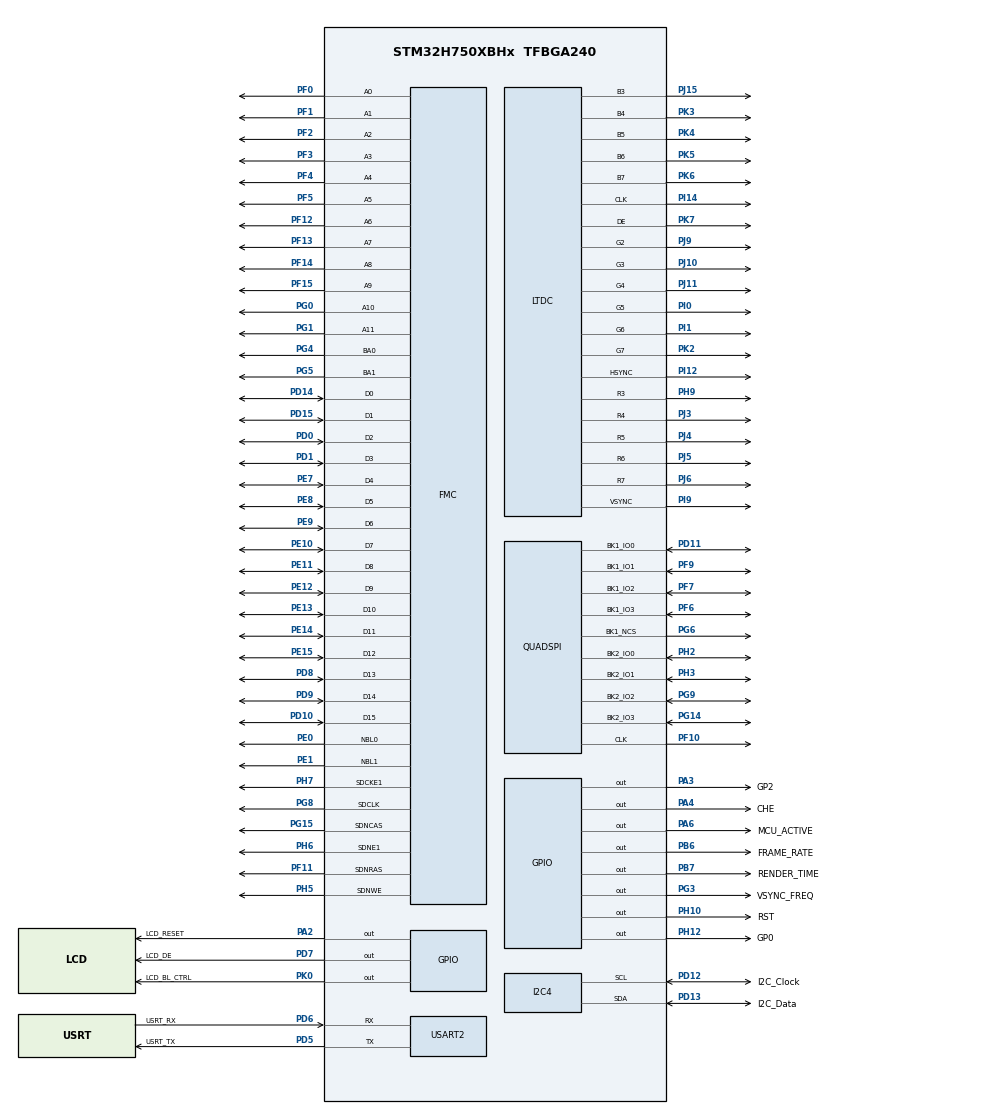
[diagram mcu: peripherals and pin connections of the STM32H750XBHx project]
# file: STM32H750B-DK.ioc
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CORTEX_M7.AccessPermission-Cortex_Memory_Protection_Unit_Region0_Settings=MPU_REGION_FULL_ACCESS
CORTEX_M7.AccessPermission-Cortex_Memory_Protection_Unit_Region1_Settings=MPU_REGION_NO_ACCESS
CORTEX_M7.AccessPermission-Cortex_Memory_Protection_Unit_Region2_Settings=MPU_REGION_FULL_ACCESS
CORTEX_M7.AccessPermission-Cortex_Memory_Protection_Unit_Region4_Settings=MPU_REGION_FULL_ACCESS
CORTEX_M7.BaseAddress-Cortex_Memory_Protection_Unit_Region0_Settings=0x24000000
CORTEX_M7.BaseAddress-Cortex_Memory_Protection_Unit_Region1_Settings=0x90000000
CORTEX_M7.BaseAddress-Cortex_Memory_Protection_Unit_Region2_Settings=0x90000000
CORTEX_M7.BaseAddress-Cortex_Memory_Protection_Unit_Region3_Settings=0xD0000000
CORTEX_M7.BaseAddress-Cortex_Memory_Protection_Unit_Region4_Settings=0xD0000000
CORTEX_M7.CPU_DCache=Enabled
CORTEX_M7.CPU_ICache=Enabled
CORTEX_M7.DisableExec-Cortex_Memory_Protection_Unit_Region0_Settings=MPU_INSTRUCTION_ACCESS_DISABLE
CORTEX_M7.DisableExec-Cortex_Memory_Protection_Unit_Region1_Settings=MPU_INSTRUCTION_ACCESS_DISABLE
CORTEX_M7.DisableExec-Cortex_Memory_Protection_Unit_Region2_Settings=MPU_INSTRUCTION_ACCESS_ENABLE
CORTEX_M7.DisableExec-Cortex_Memory_Protection_Unit_Region3_Settings=MPU_INSTRUCTION_ACCESS_DISABLE
CORTEX_M7.DisableExec-Cortex_Memory_Protection_Unit_Region4_Settings=MPU_INSTRUCTION_ACCESS_DISABLE
CORTEX_M7.Enable-Cortex_Memory_Protection_Unit_Region0_Settings=MPU_REGION_ENABLE
CORTEX_M7.Enable-Cortex_Memory_Protection_Unit_Region1_Settings=MPU_REGION_ENABLE
CORTEX_M7.Enable-Cortex_Memory_Protection_Unit_Region2_Settings=MPU_REGION_ENABLE
CORTEX_M7.Enable-Cortex_Memory_Protection_Unit_Region3_Settings=MPU_REGION_ENABLE
CORTEX_M7.Enable-Cortex_Memory_Protection_Unit_Region4_Settings=MPU_REGION_ENABLE
CORTEX_M7.IsBufferable-Cortex_Memory_Protection_Unit_Region0_Settings=MPU_ACCESS_BUFFERABLE
CORTEX_M7.IsBufferable-Cortex_Memory_Protection_Unit_Region1_Settings=MPU_ACCESS_NOT_BUFFERABLE
CORTEX_M7.IsBufferable-Cortex_Memory_Protection_Unit_Region2_Settings=MPU_ACCESS_BUFFERABLE
CORTEX_M7.IsCacheable-Cortex_Memory_Protection_Unit_Region0_Settings=MPU_ACCESS_CACHEABLE
CORTEX_M7.IsCacheable-Cortex_Memory_Protection_Unit_Region1_Settings=MPU_ACCESS_NOT_CACHEABLE
CORTEX_M7.IsCacheable-Cortex_Memory_Protection_Unit_Region2_Settings=MPU_ACCESS_CACHEABLE
CORTEX_M7.IsCacheable-Cortex_Memory_Protection_Unit_Region4_Settings=MPU_ACCESS_CACHEABLE
CORTEX_M7.IsShareable-Cortex_Memory_Protection_Unit_Region2_Settings=MPU_ACCESS_NOT_SHAREABLE
CORTEX_M7.IsShareable-Cortex_Memory_Protection_Unit_Region4_Settings=MPU_ACCESS_NOT_SHAREABLE
CORTEX_M7.MPU_Control=MPU_PRIVILEGED_DEFAULT
CORTEX_M7.Size-Cortex_Memory_Protection_Unit_Region0_Settings=MPU_REGION_SIZE_512KB
CORTEX_M7.Size-Cortex_Memory_Protection_Unit_Region1_Settings=MPU_REGION_SIZE_256MB
CORTEX_M7.Size-Cortex_Memory_Protection_Unit_Region2_Settings=MPU_REGION_SIZE_128MB
CORTEX_M7.Size-Cortex_Memory_Protection_Unit_Region3_Settings=MPU_REGION_SIZE_256MB
CORTEX_M7.Size-Cortex_Memory_Protection_Unit_Region4_Settings=MPU_REGION_SIZE_32MB
DMA2D.ColorMode=DMA2D_OUTPUT_RGB565
FMC.CASLatency2=FMC_SDRAM_CAS_LATENCY_3
FMC.ColumnBitsNumber2=FMC_SDRAM_COLUMN_BITS_NUM_8
FMC.ExitSelfRefreshDelay2=7
FMC.LoadToActiveDelay2=2
FMC.RCDDelay2=2
FMC.RPDelay2=2
FMC.ReadBurst2=FMC_SDRAM_RBURST_ENABLE
FMC.RowCycleDelay2=7
FMC.SDClockPeriod2=FMC_SDRAM_CLOCK_PERIOD_2
FMC.SelfRefreshTime2=4
FMC.WriteRecoveryTime2=5
FREERTOS.BinarySemaphores01=semaphoreHaltUntilString,Dynamic,NULL;semaphoreTransitionFromHomeByButtonSettings,Dynamic,NULL;semaphoreUART,Dynamic,NULL;semaphoreTransitionFromHomeByButtonDisconnect,Dynamic,NULL
FREERTOS.Events01=eventESPBasicSetUpFinished,Dynamic,NULL;eventESPResponseValid,Dynamic,NULL;eventESPResponse,Dynamic,NULL;eventConfigurationsLoaded,Dynamic,NULL;eventESPWifiConnected,Dynamic,NULL;eventESPServerConnected,Dynamic,NULL;eventDisconnect,Dynamic,NULL
FREERTOS.HEAP_NUMBER=4
FREERTOS.Mutexes01=MutexI2C4,Dynamic,NULL
FREERTOS.Queues01=queueTempAndHumid,16,float,0,Dynamic,NULL,NULL;queueRxDataChar,512,uint8_t,0,Dynamic,NULL,NULL;queueTouchgfxTempAndHumid,16,float,0,Dynamic,NULL,NULL
FREERTOS.Tasks01=defaultTask,24,256,StartDefaultTask,Default,NULL,Dynamic,NULL,NULL;GUITask,24,8096,TouchGFX_Task,As external,NULL,Dynamic,NULL,NULL;videoTask,8,2048,videoTaskFunc,As external,NULL,Dynamic,NULL,NULL;SendDataWithESP,32,256,prvTaskSendDataWithESP,Default,NULL,Dynamic,NULL,NULL;SetUpESP,24,256,prvTaskSetUpESP,Default,NULL,Dynamic,NULL,NULL;ReadSensorData,32,256,prvTaskReadTempAndHumidity,Default,NULL,Dynamic,NULL,NULL;ReadESP,40,256,prvTaskReadESP,Default,NULL,Dynamic,NULL,NULL;ConnectToWifi,24,256,prvTaskConnectToWifi,Default,NULL,Dynamic,NULL,NULL;ConnectToServer,24,256,prvTaskConnectToServer,Default,NULL,Dynamic,NULL,NULL;Disconnect,40,256,prvTaskDisconnect,Default,NULL,Dynamic,NULL,NULL
FREERTOS.configMINIMAL_STACK_SIZE=256
FREERTOS.configTOTAL_HEAP_SIZE=100000
FREERTOS.configUSE_APPLICATION_TASK_TAG=1
FREERTOS.configUSE_IDLE_HOOK=1
FREERTOS.configUSE_MALLOC_FAILED_HOOK=0
FREERTOS.configUSE_NEWLIB_REENTRANT=0
I2C4.Timing=0x10C0ECFF
JPEG.JPEG_RGB_FORMAT=JPEG_RGB565
LIBJPEG.RGB_ORDERING=BGR
LTDC.ActiveH=272
LTDC.ActiveW=480
LTDC.Alpha_L0=255
LTDC.BlendingFactor1_L0=LTDC_BLENDING_FACTOR1_CA
LTDC.BlendingFactor2_L0=LTDC_BLENDING_FACTOR2_CA
LTDC.HBP=3
LTDC.HSync=40
LTDC.ImageHeight_L0=272
LTDC.ImageWidth_L0=480
LTDC.Layers=0
LTDC.PixelFormat_L0=LTDC_PIXEL_FORMAT_RGB565
LTDC.VBP=3
LTDC.VSync=9
LTDC.WindowX1_L0=480
LTDC.WindowY1_L0=272
Mcu.Family=STM32H7
Mcu.Name=STM32H750XBHx
Mcu.Package=TFBGA240
Mdma.MDMA_Channel6.JPEG_OUTFIFO_TH.0.BlockCount=0
Mdma.MDMA_Channel6.JPEG_OUTFIFO_TH.0.BlockDataLength=0
Mdma.MDMA_Channel6.JPEG_OUTFIFO_TH.0.BufferTransferLength=32
Mdma.MDMA_Channel6.JPEG_OUTFIFO_TH.0.CircularMode=MDMA_LINEAR_LIST
Mdma.MDMA_Channel6.JPEG_OUTFIFO_TH.0.DataAlignment=MDMA_DATAALIGN_PACKENABLE
Mdma.MDMA_Channel6.JPEG_OUTFIFO_TH.0.DestBlockAddressOffset=0
Mdma.MDMA_Channel6.JPEG_OUTFIFO_TH.0.DestBurst=MDMA_DEST_BURST_32BEATS
Mdma.MDMA_Channel6.JPEG_OUTFIFO_TH.0.DestDataSize=MDMA_DEST_DATASIZE_BYTE
Mdma.MDMA_Channel6.JPEG_OUTFIFO_TH.0.DestinationInc=MDMA_DEST_INC_BYTE
Mdma.MDMA_Channel6.JPEG_OUTFIFO_TH.0.DstAddress=0
Mdma.MDMA_Channel6.JPEG_OUTFIFO_TH.0.Endianness=MDMA_LITTLE_ENDIANNESS_PRESERVE
Mdma.MDMA_Channel6.JPEG_OUTFIFO_TH.0.Instance=MDMA_Channel6
Mdma.MDMA_Channel6.JPEG_OUTFIFO_TH.0.MaskAddress=0
Mdma.MDMA_Channel6.JPEG_OUTFIFO_TH.0.MaskData=0
Mdma.MDMA_Channel6.JPEG_OUTFIFO_TH.0.Priority=MDMA_PRIORITY_VERY_HIGH
Mdma.MDMA_Channel6.JPEG_OUTFIFO_TH.0.Rank=First
Mdma.MDMA_Channel6.JPEG_OUTFIFO_TH.0.SourceBlockAddressOffset=0
Mdma.MDMA_Channel6.JPEG_OUTFIFO_TH.0.SourceBurst=MDMA_SOURCE_BURST_32BEATS
Mdma.MDMA_Channel6.JPEG_OUTFIFO_TH.0.SourceDataSize=MDMA_SRC_DATASIZE_WORD
Mdma.MDMA_Channel6.JPEG_OUTFIFO_TH.0.SourceInc=MDMA_SRC_INC_DISABLE
Mdma.MDMA_Channel6.JPEG_OUTFIFO_TH.0.SrcAddress=0
Mdma.MDMA_Channel6.JPEG_OUTFIFO_TH.0.TransferTriggerMode=MDMA_BUFFER_TRANSFER
Mdma.MDMA_Channel6.Request0=JPEG_OUTFIFO_TH
Mdma.MDMA_Channel6.RequestsNb=1
Mdma.MDMA_Channel7.JPEG_INFIFO_TH.0.BlockCount=0
Mdma.MDMA_Channel7.JPEG_INFIFO_TH.0.BlockDataLength=0
Mdma.MDMA_Channel7.JPEG_INFIFO_TH.0.BufferTransferLength=32
Mdma.MDMA_Channel7.JPEG_INFIFO_TH.0.CircularMode=MDMA_LINEAR_LIST
Mdma.MDMA_Channel7.JPEG_INFIFO_TH.0.DataAlignment=MDMA_DATAALIGN_PACKENABLE
Mdma.MDMA_Channel7.JPEG_INFIFO_TH.0.DestBlockAddressOffset=0
Mdma.MDMA_Channel7.JPEG_INFIFO_TH.0.DestBurst=MDMA_DEST_BURST_16BEATS
Mdma.MDMA_Channel7.JPEG_INFIFO_TH.0.DestDataSize=MDMA_DEST_DATASIZE_WORD
Mdma.MDMA_Channel7.JPEG_INFIFO_TH.0.DestinationInc=MDMA_DEST_INC_DISABLE
Mdma.MDMA_Channel7.JPEG_INFIFO_TH.0.DstAddress=0
Mdma.MDMA_Channel7.JPEG_INFIFO_TH.0.Endianness=MDMA_LITTLE_ENDIANNESS_PRESERVE
Mdma.MDMA_Channel7.JPEG_INFIFO_TH.0.Instance=MDMA_Channel7
Mdma.MDMA_Channel7.JPEG_INFIFO_TH.0.MaskAddress=0
Mdma.MDMA_Channel7.JPEG_INFIFO_TH.0.MaskData=0
Mdma.MDMA_Channel7.JPEG_INFIFO_TH.0.Priority=MDMA_PRIORITY_HIGH
Mdma.MDMA_Channel7.JPEG_INFIFO_TH.0.Rank=First
Mdma.MDMA_Channel7.JPEG_INFIFO_TH.0.SourceBlockAddressOffset=0
Mdma.MDMA_Channel7.JPEG_INFIFO_TH.0.SourceBurst=MDMA_SOURCE_BURST_32BEATS
Mdma.MDMA_Channel7.JPEG_INFIFO_TH.0.SourceDataSize=MDMA_SRC_DATASIZE_BYTE
Mdma.MDMA_Channel7.JPEG_INFIFO_TH.0.SourceInc=MDMA_SRC_INC_BYTE
Mdma.MDMA_Channel7.JPEG_INFIFO_TH.0.SrcAddress=0
Mdma.MDMA_Channel7.JPEG_INFIFO_TH.0.TransferTriggerMode=MDMA_BUFFER_TRANSFER
Mdma.MDMA_Channel7.Request0=JPEG_INFIFO_TH
Mdma.MDMA_Channel7.RequestsNb=1
Mdma.RequestSet0=MDMA_Channel7
Mdma.RequestSet1=MDMA_Channel6
Mdma.RequestSetsNb=2
NVIC.DMA2D_IRQn=true\:5\:0\:true\:false\:true\:false\:true\:true\:true
NVIC.JPEG_IRQn=true\:5\:0\:false\:false\:true\:true\:true\:true\:true
NVIC.LTDC_IRQn=true\:5\:0\:true\:false\:true\:false\:true\:true\:true
NVIC.MDMA_IRQn=true\:5\:0\:false\:false\:true\:true\:false\:true\:true
NVIC.PriorityGroup=NVIC_PRIORITYGROUP_4
NVIC.TIM6_DAC_IRQn=true\:0\:0\:false\:false\:true\:false\:false\:true\:true
NVIC.TimeBase=TIM6_DAC_IRQn
NVIC.TimeBaseIP=TIM6
NVIC.USART2_IRQn=true\:5\:0\:false\:false\:true\:true\:true\:true\:true
PA2.GPIO_Label=LCD_RESET
PA2.Signal=GPIO_Output
PA3.GPIO_Label=GP2
PA3.GPIO_PuPd=GPIO_PULLUP
PA3.PinState=GPIO_PIN_SET
PA3.Signal=GPIO_Output
PA4.GPIO_Label=CHE
PA4.GPIO_PuPd=GPIO_PULLUP
PA4.PinState=GPIO_PIN_SET
PA4.Signal=GPIO_Output
PA6.GPIO_Label=MCU_ACTIVE
PA6.GPIO_Speed=GPIO_SPEED_FREQ_VERY_HIGH
PA6.Signal=GPIO_Output
PB6.GPIO_Label=FRAME_RATE
PB6.GPIO_Speed=GPIO_SPEED_FREQ_VERY_HIGH
PB6.Signal=GPIO_Output
PB7.GPIO_Label=RENDER_TIME
PB7.GPIO_Speed=GPIO_SPEED_FREQ_VERY_HIGH
PB7.Signal=GPIO_Output
PD0.Signal=FMC_D2_DA2
PD1.Signal=FMC_D3_DA3
PD10.Signal=FMC_D15_DA15
PD11.GPIO_Speed=GPIO_SPEED_FREQ_VERY_HIGH
PD11.Mode=Dual_Bank
PD11.Signal=QUADSPI_BK1_IO0
PD12.GPIO_Label=I2C_Clock
PD12.Mode=I2C
PD12.Signal=I2C4_SCL
PD13.GPIO_Label=I2C_Data
PD13.Mode=I2C
PD13.Signal=I2C4_SDA
PD14.Signal=FMC_D0_DA0
PD15.Signal=FMC_D1_DA1
PD5.GPIO_Label=USRT_TX
PD5.GPIO_PuPd=GPIO_PULLUP
PD5.Mode=Asynchronous
PD5.Signal=USART2_TX
PD6.GPIO_Label=USRT_RX
PD6.GPIO_PuPd=GPIO_PULLUP
PD6.Mode=Asynchronous
PD6.Signal=USART2_RX
PD7.GPIO_Label=LCD_DE
PD7.Signal=GPIO_Output
PD8.Signal=FMC_D13_DA13
PD9.Signal=FMC_D14_DA14
PE0.Signal=FMC_NBL0
PE1.Signal=FMC_NBL1
PE10.Signal=FMC_D7_DA7
PE11.Signal=FMC_D8_DA8
PE12.Signal=FMC_D9_DA9
PE13.Signal=FMC_D10_DA10
PE14.Signal=FMC_D11_DA11
PE15.Signal=FMC_D12_DA12
PE7.Signal=FMC_D4_DA4
PE8.Signal=FMC_D5_DA5
PE9.Signal=FMC_D6_DA6
PF0.Signal=FMC_A0
PF1.Signal=FMC_A1
PF10.GPIO_Speed=GPIO_SPEED_FREQ_VERY_HIGH
PF10.Mode=Dual_Bank
PF10.Signal=QUADSPI_CLK
PF11.Signal=FMC_SDNRAS
PF12.Signal=FMC_A6
PF13.Signal=FMC_A7
PF14.Signal=FMC_A8
PF15.Signal=FMC_A9
PF2.Signal=FMC_A2
PF3.Signal=FMC_A3
PF4.Signal=FMC_A4
PF5.Signal=FMC_A5
PF6.GPIO_Speed=GPIO_SPEED_FREQ_VERY_HIGH
PF6.Mode=Dual_Bank
PF6.Signal=QUADSPI_BK1_IO3
PF7.GPIO_Speed=GPIO_SPEED_FREQ_VERY_HIGH
PF7.Mode=Dual_Bank
PF7.Signal=QUADSPI_BK1_IO2
PF9.GPIO_Speed=GPIO_SPEED_FREQ_VERY_HIGH
PF9.Mode=Dual_Bank
PF9.Signal=QUADSPI_BK1_IO1
PG0.Signal=FMC_A10
PG1.Signal=FMC_A11
PG14.GPIO_Speed=GPIO_SPEED_FREQ_VERY_HIGH
PG14.Mode=Dual_Bank
PG14.Signal=QUADSPI_BK2_IO3
PG15.Signal=FMC_SDNCAS
PG3.GPIO_Label=VSYNC_FREQ
PG3.GPIO_Speed=GPIO_SPEED_FREQ_VERY_HIGH
PG3.Signal=GPIO_Output
PG4.Signal=FMC_A14_BA0
PG5.Signal=FMC_A15_BA1
PG6.GPIO_Speed=GPIO_SPEED_FREQ_VERY_HIGH
PG6.Mode=Enable Chip Select 1 for both banks
PG6.Signal=QUADSPI_BK1_NCS
PG8.Signal=FMC_SDCLK
PG9.GPIO_Speed=GPIO_SPEED_FREQ_VERY_HIGH
PG9.Mode=Dual_Bank
PG9.Signal=QUADSPI_BK2_IO2
PH0-OSC_IN\ (PH0).Mode=HSE-External-Oscillator
PH0-OSC_IN\ (PH0).Signal=RCC_OSC_IN
PH1-OSC_OUT\ (PH1).Mode=HSE-External-Oscillator
PH1-OSC_OUT\ (PH1).Signal=RCC_OSC_OUT
PH10.GPIO_Label=RST
PH10.GPIO_PuPd=GPIO_PULLUP
PH10.PinState=GPIO_PIN_SET
PH10.Signal=GPIO_Output
PH12.GPIO_Label=GP0
PH12.GPIO_PuPd=GPIO_PULLUP
PH12.PinState=GPIO_PIN_SET
PH12.Signal=GPIO_Output
PH2.GPIO_Speed=GPIO_SPEED_FREQ_VERY_HIGH
PH2.Mode=Dual_Bank
PH2.Signal=QUADSPI_BK2_IO0
PH3.GPIO_Speed=GPIO_SPEED_FREQ_VERY_HIGH
PH3.Mode=Dual_Bank
PH3.Signal=QUADSPI_BK2_IO1
PH5.Signal=FMC_SDNWE
PH6.Mode=SdramChipSelect2_2
PH6.Signal=FMC_SDNE1
PH7.Mode=SdramChipSelect2_2
PH7.Signal=FMC_SDCKE1
PH9.GPIO_Speed=GPIO_SPEED_FREQ_HIGH
PH9.Mode=RGB565
PH9.Signal=LTDC_R3
PI0.GPIO_Speed=GPIO_SPEED_FREQ_HIGH
PI0.Mode=RGB565
PI0.Signal=LTDC_G5
PI1.GPIO_Speed=GPIO_SPEED_FREQ_HIGH
PI1.Mode=RGB565
PI1.Signal=LTDC_G6
PI12.GPIO_Speed=GPIO_SPEED_FREQ_HIGH
PI12.Mode=RGB565
PI12.Signal=LTDC_HSYNC
PI14.GPIO_Speed=GPIO_SPEED_FREQ_HIGH
PI14.Mode=RGB565
PI14.Signal=LTDC_CLK
PI15.GPIO_Speed=GPIO_SPEED_FREQ_HIGH
PI15.Signal=LTDC_R0
PI9.GPIO_Speed=GPIO_SPEED_FREQ_HIGH
PI9.Mode=RGB565
PI9.Signal=LTDC_VSYNC
PJ0.GPIO_Speed=GPIO_SPEED_FREQ_HIGH
PJ0.Signal=LTDC_R1
PJ1.GPIO_Speed=GPIO_SPEED_FREQ_HIGH
PJ1.Signal=LTDC_R2
PJ10.GPIO_Speed=GPIO_SPEED_FREQ_HIGH
PJ10.Mode=RGB565
PJ10.Signal=LTDC_G3
PJ11.GPIO_Speed=GPIO_SPEED_FREQ_HIGH
PJ11.Mode=RGB565
PJ11.Signal=LTDC_G4
PJ12.GPIO_Speed=GPIO_SPEED_FREQ_HIGH
PJ12.Signal=LTDC_B0
PJ13.GPIO_Speed=GPIO_SPEED_FREQ_HIGH
PJ13.Signal=LTDC_B1
PJ14.GPIO_Speed=GPIO_SPEED_FREQ_HIGH
PJ14.Signal=LTDC_B2
PJ15.GPIO_Speed=GPIO_SPEED_FREQ_HIGH
PJ15.Mode=RGB565
PJ15.Signal=LTDC_B3
PJ3.GPIO_Speed=GPIO_SPEED_FREQ_HIGH
PJ3.Mode=RGB565
PJ3.Signal=LTDC_R4
PJ4.GPIO_Speed=GPIO_SPEED_FREQ_HIGH
PJ4.Mode=RGB565
PJ4.Signal=LTDC_R5
PJ5.GPIO_Speed=GPIO_SPEED_FREQ_HIGH
PJ5.Mode=RGB565
PJ5.Signal=LTDC_R6
PJ6.GPIO_Speed=GPIO_SPEED_FREQ_HIGH
PJ6.Mode=RGB565
PJ6.Signal=LTDC_R7
PJ7.GPIO_Speed=GPIO_SPEED_FREQ_HIGH
PJ7.Signal=LTDC_G0
PJ8.GPIO_Speed=GPIO_SPEED_FREQ_HIGH
PJ8.Signal=LTDC_G1
PJ9.GPIO_Speed=GPIO_SPEED_FREQ_HIGH
PJ9.Mode=RGB565
PJ9.Signal=LTDC_G2
PK0.GPIO_Label=LCD_BL_CTRL
PK0.PinState=GPIO_PIN_SET
PK0.Signal=GPIO_Output
PK2.GPIO_Speed=GPIO_SPEED_FREQ_HIGH
PK2.Mode=RGB565
PK2.Signal=LTDC_G7
PK3.GPIO_Speed=GPIO_SPEED_FREQ_HIGH
PK3.Mode=RGB565
PK3.Signal=LTDC_B4
PK4.GPIO_Speed=GPIO_SPEED_FREQ_HIGH
PK4.Mode=RGB565
PK4.Signal=LTDC_B5
PK5.GPIO_Speed=GPIO_SPEED_FREQ_HIGH
PK5.Mode=RGB565
PK5.Signal=LTDC_B6
PK6.GPIO_Speed=GPIO_SPEED_FREQ_HIGH
PK6.Mode=RGB565
PK6.Signal=LTDC_B7
PK7.GPIO_Speed=GPIO_SPEED_FREQ_HIGH
PK7.Mode=RGB565
PK7.Signal=LTDC_DE
ProjectManager.HeapSize=0x1000
ProjectManager.StackSize=0x1000
ProjectManager.TargetToolchain=STM32CubeIDE
QUADSPI.ChipSelectHighTime=QSPI_CS_HIGH_TIME_4_CYCLE
QUADSPI.ClockMode=QSPI_CLOCK_MODE_0
QUADSPI.ClockPrescaler=3
QUADSPI.FlashSize=26
QUADSPI.SampleShifting=QSPI_SAMPLE_SHIFTING_NONE
RCC.ADCFreq_Value=50390625
RCC.APB1Freq_Value=100000000
RCC.APB2Freq_Value=100000000
RCC.APB3Freq_Value=100000000
RCC.APB4Freq_Value=100000000
RCC.CortexFreq_Value=400000000
RCC.D1PPRE=RCC_APB3_DIV2
RCC.D2PPRE1=RCC_APB1_DIV2
RCC.D2PPRE2=RCC_APB2_DIV2
RCC.D3PPRE=RCC_APB4_DIV2
RCC.DIVM1=5
RCC.DIVM3=5
RCC.DIVN1=160
RCC.DIVN3=160
RCC.DIVQ1=4
RCC.DIVR3=93
RCC.HCLKFreq_Value=200000000
RCC.HPRE=RCC_HCLK_DIV2
RCC.PLL3FRACN=0
RCC.PLLSourceVirtual=RCC_PLLSOURCE_HSE
RCC.SYSCLKFreq_VALUE=400000000
RCC.SYSCLKSource=RCC_SYSCLKSOURCE_PLLCLK
RCC.USBFreq_Value=200000000
SH.FMC_A0.0=FMC_A0,12b-sda2
SH.FMC_A1.0=FMC_A1,12b-sda2
SH.FMC_A10.0=FMC_A10,12b-sda2
SH.FMC_A11.0=FMC_A11,12b-sda2
SH.FMC_A14_BA0.0=FMC_BA0,FourSdramBanks2
SH.FMC_A15_BA1.0=FMC_BA1,FourSdramBanks2
SH.FMC_A2.0=FMC_A2,12b-sda2
SH.FMC_A3.0=FMC_A3,12b-sda2
SH.FMC_A4.0=FMC_A4,12b-sda2
SH.FMC_A5.0=FMC_A5,12b-sda2
SH.FMC_A6.0=FMC_A6,12b-sda2
SH.FMC_A7.0=FMC_A7,12b-sda2
SH.FMC_A8.0=FMC_A8,12b-sda2
SH.FMC_A9.0=FMC_A9,12b-sda2
SH.FMC_D0_DA0.0=FMC_D0,sd-16b-d2
SH.FMC_D10_DA10.0=FMC_D10,sd-16b-d2
SH.FMC_D11_DA11.0=FMC_D11,sd-16b-d2
SH.FMC_D12_DA12.0=FMC_D12,sd-16b-d2
SH.FMC_D13_DA13.0=FMC_D13,sd-16b-d2
SH.FMC_D14_DA14.0=FMC_D14,sd-16b-d2
SH.FMC_D15_DA15.0=FMC_D15,sd-16b-d2
SH.FMC_D1_DA1.0=FMC_D1,sd-16b-d2
SH.FMC_D2_DA2.0=FMC_D2,sd-16b-d2
SH.FMC_D3_DA3.0=FMC_D3,sd-16b-d2
SH.FMC_D4_DA4.0=FMC_D4,sd-16b-d2
SH.FMC_D5_DA5.0=FMC_D5,sd-16b-d2
SH.FMC_D6_DA6.0=FMC_D6,sd-16b-d2
SH.FMC_D7_DA7.0=FMC_D7,sd-16b-d2
SH.FMC_D8_DA8.0=FMC_D8,sd-16b-d2
SH.FMC_D9_DA9.0=FMC_D9,sd-16b-d2
SH.FMC_NBL0.0=FMC_NBL0,Sd2ByteEnable2
SH.FMC_NBL1.0=FMC_NBL1,Sd2ByteEnable2
SH.FMC_SDCLK.0=FMC_SDCLK,12b-sda2
SH.FMC_SDNCAS.0=FMC_SDNCAS,12b-sda2
SH.FMC_SDNRAS.0=FMC_SDNRAS,12b-sda2
SH.FMC_SDNWE.0=FMC_SDNWE,12b-sda2
USART2.VirtualMode-Asynchronous=VM_ASYNC
VP_CRC_VS_CRC.Mode=CRC_Activate
VP_DMA2D_VS_DMA2D.Mode=DMA2D_Activate
VP_FREERTOS_VS_CMSIS_V2.Mode=CMSIS_V2
VP_JPEG_VS_JPEG.Mode=JPEG_Activate
VP_LIBJPEG_VS_JPEGLIB.Mode=Enabled
VP_SYS_VS_tim6.Mode=TIM6
board=custom

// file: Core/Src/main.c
/* USER CODE BEGIN Header */
/**
  ******************************************************************************
  * @file           : main.c
  * @brief          : Main program body
  ******************************************************************************
  * @attention
  *
  * <h2><center>&copy; Copyright (c) 2020 STMicroelectronics.
  * All rights reserved.</center></h2>
  *
  * This software component is licensed by ST under Ultimate Liberty license
  * SLA0044, the "License"; You may not use this file except in compliance with
  * the License. You may obtain a copy of the License at:
  *                             www.st.com/SLA0044
  *
  ******************************************************************************
  */
/* USER CODE END Header */
#include "main.h"
#include "cmsis_os.h"
#include "libjpeg.h"

/* USER CODE BEGIN Includes */
#include "stm32h750b_discovery_qspi.h"
#include "stm32h750b_discovery_sdram.h"

#include "sht3x.h"
#include <stdbool.h>
#include <stdio.h>
#include <string.h>
#include <stdarg.h>
#include <stddef.h>

#include "app_touchgfx.h"
/* USER CODE END Includes */

CRC_HandleTypeDef hcrc;

DMA2D_HandleTypeDef hdma2d;

I2C_HandleTypeDef hi2c4;

JPEG_HandleTypeDef hjpeg;
MDMA_HandleTypeDef hmdma_jpeg_infifo_th;
MDMA_HandleTypeDef hmdma_jpeg_outfifo_th;

LTDC_HandleTypeDef hltdc;

QSPI_HandleTypeDef hqspi;

UART_HandleTypeDef huart2;

SDRAM_HandleTypeDef hsdram2;

/* Definitions for defaultTask */
osThreadId_t defaultTaskHandle;
const osThreadAttr_t defaultTask_attributes = {
  .name = "defaultTask",
  .stack_size = 256 * 4,
  .priority = (osPriority_t) osPriorityNormal,
};
/* Definitions for GUITask */
osThreadId_t GUITaskHandle;
const osThreadAttr_t GUITask_attributes = {
  .name = "GUITask",
  .stack_size = 8096 * 4,
  .priority = (osPriority_t) osPriorityNormal,
};
/* Definitions for videoTask */
osThreadId_t videoTaskHandle;
const osThreadAttr_t videoTask_attributes = {
  .name = "videoTask",
  .stack_size = 2048 * 4,
  .priority = (osPriority_t) osPriorityLow,
};
/* Definitions for SendDataWithESP */
osThreadId_t SendDataWithESPHandle;
const osThreadAttr_t SendDataWithESP_attributes = {
  .name = "SendDataWithESP",
  .stack_size = 256 * 4,
  .priority = (osPriority_t) osPriorityAboveNormal,
};
/* Definitions for SetUpESP */
osThreadId_t SetUpESPHandle;
const osThreadAttr_t SetUpESP_attributes = {
  .name = "SetUpESP",
  .stack_size = 256 * 4,
  .priority = (osPriority_t) osPriorityNormal,
};
/* Definitions for ReadSensorData */
osThreadId_t ReadSensorDataHandle;
const osThreadAttr_t ReadSensorData_attributes = {
  .name = "ReadSensorData",
  .stack_size = 256 * 4,
  .priority = (osPriority_t) osPriorityAboveNormal,
};
/* Definitions for ReadESP */
osThreadId_t ReadESPHandle;
const osThreadAttr_t ReadESP_attributes = {
  .name = "ReadESP",
  .stack_size = 256 * 4,
  .priority = (osPriority_t) osPriorityHigh,
};
/* Definitions for ConnectToWifi */
osThreadId_t ConnectToWifiHandle;
const osThreadAttr_t ConnectToWifi_attributes = {
  .name = "ConnectToWifi",
  .stack_size = 256 * 4,
  .priority = (osPriority_t) osPriorityNormal,
};
/* Definitions for ConnectToServer */
osThreadId_t ConnectToServerHandle;
const osThreadAttr_t ConnectToServer_attributes = {
  .name = "ConnectToServer",
  .stack_size = 256 * 4,
  .priority = (osPriority_t) osPriorityNormal,
};
/* Definitions for Disconnect */
osThreadId_t DisconnectHandle;
const osThreadAttr_t Disconnect_attributes = {
  .name = "Disconnect",
  .stack_size = 256 * 4,
  .priority = (osPriority_t) osPriorityHigh,
};
/* Definitions for queueTempAndHumid */
osMessageQueueId_t queueTempAndHumidHandle;
const osMessageQueueAttr_t queueTempAndHumid_attributes = {
  .name = "queueTempAndHumid"
};
/* Definitions for queueRxDataChar */
osMessageQueueId_t queueRxDataCharHandle;
const osMessageQueueAttr_t queueRxDataChar_attributes = {
  .name = "queueRxDataChar"
};
/* Definitions for queueTouchgfxTempAndHumid */
osMessageQueueId_t queueTouchgfxTempAndHumidHandle;
const osMessageQueueAttr_t queueTouchgfxTempAndHumid_attributes = {
  .name = "queueTouchgfxTempAndHumid"
};
/* Definitions for MutexI2C4 */
osMutexId_t MutexI2C4Handle;
const osMutexAttr_t MutexI2C4_attributes = {
  .name = "MutexI2C4"
};
/* Definitions for semaphoreHaltUntilString */
osSemaphoreId_t semaphoreHaltUntilStringHandle;
const osSemaphoreAttr_t semaphoreHaltUntilString_attributes = {
  .name = "semaphoreHaltUntilString"
};
/* Definitions for semaphoreTransitionFromHomeByButtonSettings */
osSemaphoreId_t semaphoreTransitionFromHomeByButtonSettingsHandle;
const osSemaphoreAttr_t semaphoreTransitionFromHomeByButtonSettings_attributes = {
  .name = "semaphoreTransitionFromHomeByButtonSettings"
};
/* Definitions for semaphoreUART */
osSemaphoreId_t semaphoreUARTHandle;
const osSemaphoreAttr_t semaphoreUART_attributes = {
  .name = "semaphoreUART"
};
/* Definitions for semaphoreTransitionFromHomeByButtonDisconnect */
osSemaphoreId_t semaphoreTransitionFromHomeByButtonDisconnectHandle;
const osSemaphoreAttr_t semaphoreTransitionFromHomeByButtonDisconnect_attributes = {
  .name = "semaphoreTransitionFromHomeByButtonDisconnect"
};
/* Definitions for eventESPBasicSetUpFinished */
osEventFlagsId_t eventESPBasicSetUpFinishedHandle;
const osEventFlagsAttr_t eventESPBasicSetUpFinished_attributes = {
  .name = "eventESPBasicSetUpFinished"
};
/* Definitions for eventESPResponseValid */
osEventFlagsId_t eventESPResponseValidHandle;
const osEventFlagsAttr_t eventESPResponseValid_attributes = {
  .name = "eventESPResponseValid"
};
/* Definitions for eventESPResponse */
osEventFlagsId_t eventESPResponseHandle;
const osEventFlagsAttr_t eventESPResponse_attributes = {
  .name = "eventESPResponse"
};
/* Definitions for eventConfigurationsLoaded */
osEventFlagsId_t eventConfigurationsLoadedHandle;
const osEventFlagsAttr_t eventConfigurationsLoaded_attributes = {
  .name = "eventConfigurationsLoaded"
};
/* Definitions for eventESPWifiConnected */
osEventFlagsId_t eventESPWifiConnectedHandle;
const osEventFlagsAttr_t eventESPWifiConnected_attributes = {
  .name = "eventESPWifiConnected"
};
/* Definitions for eventESPServerConnected */
osEventFlagsId_t eventESPServerConnectedHandle;
const osEventFlagsAttr_t eventESPServerConnected_attributes = {
  .name = "eventESPServerConnected"
};
/* Definitions for eventDisconnect */
osEventFlagsId_t eventDisconnectHandle;
const osEventFlagsAttr_t eventDisconnect_attributes = {
  .name = "eventDisconnect"
};
/* USER CODE BEGIN PV */
// Sensor handle
sht3x_handle_t sht31 = {&hi2c4, SHT3X_I2C_DEVICE_ADDRESS_ADDR_PIN_LOW};
enum state {	STATE_CONNECT_WIFI, STATE_CONNECT_SERVER, STATE_SEND_CIPSEND, STATE_SEND_DATA,
				STATE_SEND_ATE0, STATE_READY, STATE_ERROR, STATE_CONFIG};
enum state currentState = STATE_READY;

uint8_t received_message[RECEIVED_MESSAGE_SIZE] = {'\0'};
uint8_t rx_buffer;	// Global variable for UART callback func.
uint8_t expectedESPResponse[64] = {'\0'};

char server_ip[50];
char server_port[50];
char wifi_ssid[50];
char wifi_pass[50];
uint16_t data_frequency = 0;
/* USER CODE END PV */

void SystemClock_Config(void);
static void MPU_Initialize(void);
static void MPU_Config(void);
static void MX_GPIO_Init(void);
static void MX_MDMA_Init(void);
static void MX_LTDC_Init(void);
static void MX_DMA2D_Init(void);
static void MX_QUADSPI_Init(void);
static void MX_FMC_Init(void);
static void MX_JPEG_Init(void);
static void MX_CRC_Init(void);
static void MX_I2C4_Init(void);
static void MX_USART2_UART_Init(void);
void StartDefaultTask(void *argument);
extern void TouchGFX_Task(void *argument);
extern void videoTaskFunc(void *argument);
void prvTaskSendDataWithESP(void *argument);
void prvTaskSetUpESP(void *argument);
void prvTaskReadTempAndHumidity(void *argument);
void prvTaskReadESP(void *argument);
void prvTaskConnectToWifi(void *argument);
void prvTaskConnectToServer(void *argument);
void prvTaskDisconnect(void *argument);

int main(void)
{

  /* Enable I-Cache---------------------------------------------------------*/
  SCB_EnableICache();

  /* Enable D-Cache---------------------------------------------------------*/
  SCB_EnableDCache();

  /* MCU Configuration--------------------------------------------------------*/

  /* Reset of all peripherals, Initializes the Flash interface and the Systick. */
  HAL_Init();

  /* MPU Configuration--------------------------------------------------------*/
  MPU_Config();

  /* Configure the system clock */
  SystemClock_Config();

  /* USER CODE BEGIN SysInit */
  /* Explicit enabling interrupt to support debugging in CubeIDE when using external flash loader */
  __enable_irq();
  /* USER CODE END SysInit */

  /* Initialize all configured peripherals */
  MX_GPIO_Init();
  MX_MDMA_Init();
  MX_LTDC_Init();
  MX_DMA2D_Init();
  MX_FMC_Init();
  MX_LIBJPEG_Init();
  MX_JPEG_Init();
  MX_CRC_Init();
  MX_I2C4_Init();
  MX_USART2_UART_Init();

  /* Init scheduler */
  osKernelInitialize();
  /* Create the mutex(es) */
  /* creation of MutexI2C4 */
  MutexI2C4Handle = osMutexNew(&MutexI2C4_attributes);

  /* Create the semaphores(s) */
  /* creation of semaphoreHaltUntilString */
  semaphoreHaltUntilStringHandle = osSemaphoreNew(1, 1, &semaphoreHaltUntilString_attributes);

  /* creation of semaphoreTransitionFromHomeByButtonSettings */
  semaphoreTransitionFromHomeByButtonSettingsHandle = osSemaphoreNew(1, 1, &semaphoreTransitionFromHomeByButtonSettings_attributes);

  /* creation of semaphoreUART */
  semaphoreUARTHandle = osSemaphoreNew(1, 1, &semaphoreUART_attributes);

  /* creation of semaphoreTransitionFromHomeByButtonDisconnect */
  semaphoreTransitionFromHomeByButtonDisconnectHandle = osSemaphoreNew(1, 1, &semaphoreTransitionFromHomeByButtonDisconnect_attributes);

  /* Create the queue(s) */
  /* creation of queueTempAndHumid */
  queueTempAndHumidHandle = osMessageQueueNew (16, sizeof(float), &queueTempAndHumid_attributes);

  /* creation of queueRxDataChar */
  queueRxDataCharHandle = osMessageQueueNew (512, sizeof(uint8_t), &queueRxDataChar_attributes);

  /* creation of queueTouchgfxTempAndHumid */
  queueTouchgfxTempAndHumidHandle = osMessageQueueNew (16, sizeof(float), &queueTouchgfxTempAndHumid_attributes);

  /* Create the thread(s) */
  /* creation of defaultTask */
  defaultTaskHandle = osThreadNew(StartDefaultTask, NULL, &defaultTask_attributes);

  /* creation of GUITask */
  GUITaskHandle = osThreadNew(TouchGFX_Task, NULL, &GUITask_attributes);

  /* creation of videoTask */
  videoTaskHandle = osThreadNew(videoTaskFunc, NULL, &videoTask_attributes);

  /* creation of SendDataWithESP */
  SendDataWithESPHandle = osThreadNew(prvTaskSendDataWithESP, NULL, &SendDataWithESP_attributes);

  /* creation of SetUpESP */
  SetUpESPHandle = osThreadNew(prvTaskSetUpESP, NULL, &SetUpESP_attributes);

  /* creation of ReadSensorData */
  ReadSensorDataHandle = osThreadNew(prvTaskReadTempAndHumidity, NULL, &ReadSensorData_attributes);

  /* creation of ReadESP */
  ReadESPHandle = osThreadNew(prvTaskReadESP, NULL, &ReadESP_attributes);

  /* creation of ConnectToWifi */
  ConnectToWifiHandle = osThreadNew(prvTaskConnectToWifi, NULL, &ConnectToWifi_attributes);

  /* creation of ConnectToServer */
  ConnectToServerHandle = osThreadNew(prvTaskConnectToServer, NULL, &ConnectToServer_attributes);

  /* creation of Disconnect */
  DisconnectHandle = osThreadNew(prvTaskDisconnect, NULL, &Disconnect_attributes);

  /* creation of eventESPBasicSetUpFinished */
  eventESPBasicSetUpFinishedHandle = osEventFlagsNew(&eventESPBasicSetUpFinished_attributes);

  /* creation of eventESPResponseValid */
  eventESPResponseValidHandle = osEventFlagsNew(&eventESPResponseValid_attributes);

  /* creation of eventESPResponse */
  eventESPResponseHandle = osEventFlagsNew(&eventESPResponse_attributes);

  /* creation of eventConfigurationsLoaded */
  eventConfigurationsLoadedHandle = osEventFlagsNew(&eventConfigurationsLoaded_attributes);

  /* creation of eventESPWifiConnected */
  eventESPWifiConnectedHandle = osEventFlagsNew(&eventESPWifiConnected_attributes);

  /* creation of eventESPServerConnected */
  eventESPServerConnectedHandle = osEventFlagsNew(&eventESPServerConnected_attributes);

  /* creation of eventDisconnect */
  eventDisconnectHandle = osEventFlagsNew(&eventDisconnect_attributes);

  /* USER CODE BEGIN RTOS_EVENTS */
  /* add events, ... */
  // Enable UART interrupts
  HAL_UART_Receive_IT(&huart2, &rx_buffer, 1);
  __HAL_UART_ENABLE_IT(&huart2, UART_IT_RXNE);
  // Take semaphore because transition has not occurred when setting up
  osSemaphoreAcquire(semaphoreTransitionFromHomeByButtonSettingsHandle, osWaitForever);
  osSemaphoreAcquire(semaphoreTransitionFromHomeByButtonDisconnectHandle, osWaitForever);

  MX_TouchGFX_Init();
  /* USER CODE END RTOS_EVENTS */

  /* Start scheduler */
  osKernelStart();

  /* We should never get here as control is now taken by the scheduler */
  /* Infinite loop */
  while (1)
  {

  }
}

void SystemClock_Config(void)
{
  RCC_OscInitTypeDef RCC_OscInitStruct = {0};
  RCC_ClkInitTypeDef RCC_ClkInitStruct = {0};

  /** Supply configuration update enable
  */
  HAL_PWREx_ConfigSupply(PWR_LDO_SUPPLY);

  /** Configure the main internal regulator output voltage
  */
  __HAL_PWR_VOLTAGESCALING_CONFIG(PWR_REGULATOR_VOLTAGE_SCALE1);

  while(!__HAL_PWR_GET_FLAG(PWR_FLAG_VOSRDY)) {}

  /** Initializes the RCC Oscillators according to the specified parameters
  * in the RCC_OscInitTypeDef structure.
  */
  RCC_OscInitStruct.OscillatorType = RCC_OSCILLATORTYPE_HSE;
  RCC_OscInitStruct.HSEState = RCC_HSE_ON;
  RCC_OscInitStruct.PLL.PLLState = RCC_PLL_ON;
  RCC_OscInitStruct.PLL.PLLSource = RCC_PLLSOURCE_HSE;
  RCC_OscInitStruct.PLL.PLLM = 5;
  RCC_OscInitStruct.PLL.PLLN = 160;
  RCC_OscInitStruct.PLL.PLLP = 2;
  RCC_OscInitStruct.PLL.PLLQ = 4;
  RCC_OscInitStruct.PLL.PLLR = 2;
  RCC_OscInitStruct.PLL.PLLRGE = RCC_PLL1VCIRANGE_2;
  RCC_OscInitStruct.PLL.PLLVCOSEL = RCC_PLL1VCOWIDE;
  RCC_OscInitStruct.PLL.PLLFRACN = 0;
  if (HAL_RCC_OscConfig(&RCC_OscInitStruct) != HAL_OK)
  {
    Error_Handler();
  }

  /** Initializes the CPU, AHB and APB buses clocks
  */
  RCC_ClkInitStruct.ClockType = RCC_CLOCKTYPE_HCLK|RCC_CLOCKTYPE_SYSCLK
                              |RCC_CLOCKTYPE_PCLK1|RCC_CLOCKTYPE_PCLK2
                              |RCC_CLOCKTYPE_D3PCLK1|RCC_CLOCKTYPE_D1PCLK1;
  RCC_ClkInitStruct.SYSCLKSource = RCC_SYSCLKSOURCE_PLLCLK;
  RCC_ClkInitStruct.SYSCLKDivider = RCC_SYSCLK_DIV1;
  RCC_ClkInitStruct.AHBCLKDivider = RCC_HCLK_DIV2;
  RCC_ClkInitStruct.APB3CLKDivider = RCC_APB3_DIV2;
  RCC_ClkInitStruct.APB1CLKDivider = RCC_APB1_DIV2;
  RCC_ClkInitStruct.APB2CLKDivider = RCC_APB2_DIV2;
  RCC_ClkInitStruct.APB4CLKDivider = RCC_APB4_DIV2;

  if (HAL_RCC_ClockConfig(&RCC_ClkInitStruct, FLASH_LATENCY_2) != HAL_OK)
  {
    Error_Handler();
  }
}

static void MX_CRC_Init(void)
{

  hcrc.Instance = CRC;
  hcrc.Init.DefaultPolynomialUse = DEFAULT_POLYNOMIAL_ENABLE;
  hcrc.Init.DefaultInitValueUse = DEFAULT_INIT_VALUE_ENABLE;
  hcrc.Init.InputDataInversionMode = CRC_INPUTDATA_INVERSION_NONE;
  hcrc.Init.OutputDataInversionMode = CRC_OUTPUTDATA_INVERSION_DISABLE;
  hcrc.InputDataFormat = CRC_INPUTDATA_FORMAT_BYTES;
  if (HAL_CRC_Init(&hcrc) != HAL_OK)
  {
    Error_Handler();
  }

}

static void MX_DMA2D_Init(void)
{

  hdma2d.Instance = DMA2D;
  hdma2d.Init.Mode = DMA2D_M2M;
  hdma2d.Init.ColorMode = DMA2D_OUTPUT_RGB565;
  hdma2d.Init.OutputOffset = 0;
  hdma2d.LayerCfg[1].InputOffset = 0;
  hdma2d.LayerCfg[1].InputColorMode = DMA2D_INPUT_RGB565;
  hdma2d.LayerCfg[1].AlphaMode = DMA2D_NO_MODIF_ALPHA;
  hdma2d.LayerCfg[1].InputAlpha = 0;
  hdma2d.LayerCfg[1].AlphaInverted = DMA2D_REGULAR_ALPHA;
  hdma2d.LayerCfg[1].RedBlueSwap = DMA2D_RB_REGULAR;
  hdma2d.LayerCfg[1].ChromaSubSampling = DMA2D_NO_CSS;
  if (HAL_DMA2D_Init(&hdma2d) != HAL_OK)
  {
    Error_Handler();
  }
  if (HAL_DMA2D_ConfigLayer(&hdma2d, 1) != HAL_OK)
  {
    Error_Handler();
  }

}

static void MX_I2C4_Init(void)
{

  hi2c4.Instance = I2C4;
  hi2c4.Init.Timing = 0x10C0ECFF;
  hi2c4.Init.OwnAddress1 = 0;
  hi2c4.Init.AddressingMode = I2C_ADDRESSINGMODE_7BIT;
  hi2c4.Init.DualAddressMode = I2C_DUALADDRESS_DISABLE;
  hi2c4.Init.OwnAddress2 = 0;
  hi2c4.Init.OwnAddress2Masks = I2C_OA2_NOMASK;
  hi2c4.Init.GeneralCallMode = I2C_GENERALCALL_DISABLE;
  hi2c4.Init.NoStretchMode = I2C_NOSTRETCH_DISABLE;
  if (HAL_I2C_Init(&hi2c4) != HAL_OK)
  {
    Error_Handler();
  }

  /** Configure Analogue filter
  */
  if (HAL_I2CEx_ConfigAnalogFilter(&hi2c4, I2C_ANALOGFILTER_ENABLE) != HAL_OK)
  {
    Error_Handler();
  }

  /** Configure Digital filter
  */
  if (HAL_I2CEx_ConfigDigitalFilter(&hi2c4, 0) != HAL_OK)
  {
    Error_Handler();
  }

}

static void MX_JPEG_Init(void)
{

  hjpeg.Instance = JPEG;
  if (HAL_JPEG_Init(&hjpeg) != HAL_OK)
  {
    Error_Handler();
  }

}

static void MX_LTDC_Init(void)
{

  LTDC_LayerCfgTypeDef pLayerCfg = {0};

  hltdc.Instance = LTDC;
  hltdc.Init.HSPolarity = LTDC_HSPOLARITY_AL;
  hltdc.Init.VSPolarity = LTDC_VSPOLARITY_AL;
  hltdc.Init.DEPolarity = LTDC_DEPOLARITY_AL;
  hltdc.Init.PCPolarity = LTDC_PCPOLARITY_IPC;
  hltdc.Init.HorizontalSync = 39;
  hltdc.Init.VerticalSync = 8;
  hltdc.Init.AccumulatedHBP = 42;
  hltdc.Init.AccumulatedVBP = 11;
  hltdc.Init.AccumulatedActiveW = 522;
  hltdc.Init.AccumulatedActiveH = 283;
  hltdc.Init.TotalWidth = 528;
  hltdc.Init.TotalHeigh = 285;
  hltdc.Init.Backcolor.Blue = 0;
  hltdc.Init.Backcolor.Green = 0;
  hltdc.Init.Backcolor.Red = 0;
  if (HAL_LTDC_Init(&hltdc) != HAL_OK)
  {
    Error_Handler();
  }
  pLayerCfg.WindowX0 = 0;
  pLayerCfg.WindowX1 = 480;
  pLayerCfg.WindowY0 = 0;
  pLayerCfg.WindowY1 = 272;
  pLayerCfg.PixelFormat = LTDC_PIXEL_FORMAT_RGB565;
  pLayerCfg.Alpha = 255;
  pLayerCfg.Alpha0 = 0;
  pLayerCfg.BlendingFactor1 = LTDC_BLENDING_FACTOR1_CA;
  pLayerCfg.BlendingFactor2 = LTDC_BLENDING_FACTOR2_CA;
  pLayerCfg.FBStartAdress = 0;
  pLayerCfg.ImageWidth = 480;
  pLayerCfg.ImageHeight = 272;
  pLayerCfg.Backcolor.Blue = 0;
  pLayerCfg.Backcolor.Green = 0;
  pLayerCfg.Backcolor.Red = 0;
  if (HAL_LTDC_ConfigLayer(&hltdc, &pLayerCfg, 0) != HAL_OK)
  {
    Error_Handler();
  }

}

static void MX_QUADSPI_Init(void)
{

  /* USER CODE BEGIN QUADSPI_Init 0 */
  BSP_QSPI_Init_t qspi_initParams ;
  /* USER CODE END QUADSPI_Init 0 */

  /* QUADSPI parameter configuration*/
  hqspi.Instance = QUADSPI;
  hqspi.Init.ClockPrescaler = 3;
  hqspi.Init.FifoThreshold = 1;
  hqspi.Init.SampleShifting = QSPI_SAMPLE_SHIFTING_NONE;
  hqspi.Init.FlashSize = 26;
  hqspi.Init.ChipSelectHighTime = QSPI_CS_HIGH_TIME_4_CYCLE;
  hqspi.Init.ClockMode = QSPI_CLOCK_MODE_0;
  hqspi.Init.DualFlash = QSPI_DUALFLASH_ENABLE;
  if (HAL_QSPI_Init(&hqspi) != HAL_OK)
  {
    Error_Handler();
  }
  /* USER CODE BEGIN QUADSPI_Init 2 */
  qspi_initParams.InterfaceMode = MT25TL01G_QPI_MODE;
  qspi_initParams.TransferRate  = MT25TL01G_DTR_TRANSFER ;
  qspi_initParams.DualFlashMode = MT25TL01G_DUALFLASH_ENABLE;
  BSP_QSPI_DeInit(0);
  if (BSP_QSPI_Init(0, &qspi_initParams) != BSP_ERROR_NONE)
  {
    Error_Handler( );
  }
  if(BSP_QSPI_EnableMemoryMappedMode(0) != BSP_ERROR_NONE)
  {
    Error_Handler( );
  }
  /* USER CODE END QUADSPI_Init 2 */

}

static void MX_USART2_UART_Init(void)
{

  huart2.Instance = USART2;
  huart2.Init.BaudRate = 115200;
  huart2.Init.WordLength = UART_WORDLENGTH_8B;
  huart2.Init.StopBits = UART_STOPBITS_1;
  huart2.Init.Parity = UART_PARITY_NONE;
  huart2.Init.Mode = UART_MODE_TX_RX;
  huart2.Init.HwFlowCtl = UART_HWCONTROL_NONE;
  huart2.Init.OverSampling = UART_OVERSAMPLING_16;
  huart2.Init.OneBitSampling = UART_ONE_BIT_SAMPLE_DISABLE;
  huart2.Init.ClockPrescaler = UART_PRESCALER_DIV1;
  huart2.AdvancedInit.AdvFeatureInit = UART_ADVFEATURE_NO_INIT;
  if (HAL_UART_Init(&huart2) != HAL_OK)
  {
    Error_Handler();
  }
  if (HAL_UARTEx_SetTxFifoThreshold(&huart2, UART_TXFIFO_THRESHOLD_1_8) != HAL_OK)
  {
    Error_Handler();
  }
  if (HAL_UARTEx_SetRxFifoThreshold(&huart2, UART_RXFIFO_THRESHOLD_1_8) != HAL_OK)
  {
    Error_Handler();
  }
  if (HAL_UARTEx_DisableFifoMode(&huart2) != HAL_OK)
  {
    Error_Handler();
  }

}

/**
  * Enable MDMA controller clock
  */
static void MX_MDMA_Init(void)
{

  /* MDMA controller clock enable */
  __HAL_RCC_MDMA_CLK_ENABLE();
  /* Local variables */

  /* MDMA interrupt initialization */
  /* MDMA_IRQn interrupt configuration */
  HAL_NVIC_SetPriority(MDMA_IRQn, 5, 0);
  HAL_NVIC_EnableIRQ(MDMA_IRQn);

}

/* FMC initialization function */
static void MX_FMC_Init(void)
{

  FMC_SDRAM_TimingTypeDef SdramTiming = {0};

  /** Perform the SDRAM2 memory initialization sequence
  */
  hsdram2.Instance = FMC_SDRAM_DEVICE;
  /* hsdram2.Init */
  hsdram2.Init.SDBank = FMC_SDRAM_BANK2;
  hsdram2.Init.ColumnBitsNumber = FMC_SDRAM_COLUMN_BITS_NUM_8;
  hsdram2.Init.RowBitsNumber = FMC_SDRAM_ROW_BITS_NUM_12;
  hsdram2.Init.MemoryDataWidth = FMC_SDRAM_MEM_BUS_WIDTH_16;
  hsdram2.Init.InternalBankNumber = FMC_SDRAM_INTERN_BANKS_NUM_4;
  hsdram2.Init.CASLatency = FMC_SDRAM_CAS_LATENCY_3;
  hsdram2.Init.WriteProtection = FMC_SDRAM_WRITE_PROTECTION_DISABLE;
  hsdram2.Init.SDClockPeriod = FMC_SDRAM_CLOCK_PERIOD_2;
  hsdram2.Init.ReadBurst = FMC_SDRAM_RBURST_ENABLE;
  hsdram2.Init.ReadPipeDelay = FMC_SDRAM_RPIPE_DELAY_0;
  /* SdramTiming */
  SdramTiming.LoadToActiveDelay = 2;
  SdramTiming.ExitSelfRefreshDelay = 7;
  SdramTiming.SelfRefreshTime = 4;
  SdramTiming.RowCycleDelay = 7;
  SdramTiming.WriteRecoveryTime = 5;
  SdramTiming.RPDelay = 2;
  SdramTiming.RCDDelay = 2;

  if (HAL_SDRAM_Init(&hsdram2, &SdramTiming) != HAL_OK)
  {
    Error_Handler( );
  }

  /* USER CODE BEGIN FMC_Init 2 */
  BSP_SDRAM_DeInit(0);
  if(BSP_SDRAM_Init(0) != BSP_ERROR_NONE)
  {
    Error_Handler( );
  }
  /* USER CODE END FMC_Init 2 */
}

static void MX_GPIO_Init(void)
{
  GPIO_InitTypeDef GPIO_InitStruct = {0};

  /* GPIO Ports Clock Enable */
  __HAL_RCC_GPIOK_CLK_ENABLE();
  __HAL_RCC_GPIOG_CLK_ENABLE();
  __HAL_RCC_GPIOD_CLK_ENABLE();
  __HAL_RCC_GPIOI_CLK_ENABLE();
  __HAL_RCC_GPIOE_CLK_ENABLE();
  __HAL_RCC_GPIOB_CLK_ENABLE();
  __HAL_RCC_GPIOJ_CLK_ENABLE();
  __HAL_RCC_GPIOF_CLK_ENABLE();
  __HAL_RCC_GPIOH_CLK_ENABLE();
  __HAL_RCC_GPIOA_CLK_ENABLE();

  /*Configure GPIO pin Output Level */
  HAL_GPIO_WritePin(GPIOB, FRAME_RATE_Pin|RENDER_TIME_Pin, GPIO_PIN_RESET);

  /*Configure GPIO pin Output Level */
  HAL_GPIO_WritePin(LCD_DE_GPIO_Port, LCD_DE_Pin, GPIO_PIN_RESET);

  /*Configure GPIO pin Output Level */
  HAL_GPIO_WritePin(VSYNC_FREQ_GPIO_Port, VSYNC_FREQ_Pin, GPIO_PIN_RESET);

  /*Configure GPIO pin Output Level */
  HAL_GPIO_WritePin(LCD_BL_CTRL_GPIO_Port, LCD_BL_CTRL_Pin, GPIO_PIN_SET);

  /*Configure GPIO pin Output Level */
  HAL_GPIO_WritePin(GPIOA, LCD_RESET_Pin|MCU_ACTIVE_Pin, GPIO_PIN_RESET);

  /*Configure GPIO pin Output Level */
  HAL_GPIO_WritePin(GPIOH, RST_Pin|GP0_Pin, GPIO_PIN_SET);

  /*Configure GPIO pin Output Level */
  HAL_GPIO_WritePin(GPIOA, GP2_Pin|CHE_Pin, GPIO_PIN_SET);

  /*Configure GPIO pins : FRAME_RATE_Pin RENDER_TIME_Pin */
  GPIO_InitStruct.Pin = FRAME_RATE_Pin|RENDER_TIME_Pin;
  GPIO_InitStruct.Mode = GPIO_MODE_OUTPUT_PP;
  GPIO_InitStruct.Pull = GPIO_NOPULL;
  GPIO_InitStruct.Speed = GPIO_SPEED_FREQ_VERY_HIGH;
  HAL_GPIO_Init(GPIOB, &GPIO_InitStruct);

  /*Configure GPIO pin : LCD_DE_Pin */
  GPIO_InitStruct.Pin = LCD_DE_Pin;
  GPIO_InitStruct.Mode = GPIO_MODE_OUTPUT_PP;
  GPIO_InitStruct.Pull = GPIO_NOPULL;
  GPIO_InitStruct.Speed = GPIO_SPEED_FREQ_LOW;
  HAL_GPIO_Init(LCD_DE_GPIO_Port, &GPIO_InitStruct);

  /*Configure GPIO pin : VSYNC_FREQ_Pin */
  GPIO_InitStruct.Pin = VSYNC_FREQ_Pin;
  GPIO_InitStruct.Mode = GPIO_MODE_OUTPUT_PP;
  GPIO_InitStruct.Pull = GPIO_NOPULL;
  GPIO_InitStruct.Speed = GPIO_SPEED_FREQ_VERY_HIGH;
  HAL_GPIO_Init(VSYNC_FREQ_GPIO_Port, &GPIO_InitStruct);

  /*Configure GPIO pin : LCD_BL_CTRL_Pin */
  GPIO_InitStruct.Pin = LCD_BL_CTRL_Pin;
  GPIO_InitStruct.Mode = GPIO_MODE_OUTPUT_PP;
  GPIO_InitStruct.Pull = GPIO_NOPULL;
  GPIO_InitStruct.Speed = GPIO_SPEED_FREQ_LOW;
  HAL_GPIO_Init(LCD_BL_CTRL_GPIO_Port, &GPIO_InitStruct);

  /*Configure GPIO pin : LCD_RESET_Pin */
  GPIO_InitStruct.Pin = LCD_RESET_Pin;
  GPIO_InitStruct.Mode = GPIO_MODE_OUTPUT_PP;
  GPIO_InitStruct.Pull = GPIO_NOPULL;
  GPIO_InitStruct.Speed = GPIO_SPEED_FREQ_LOW;
  HAL_GPIO_Init(LCD_RESET_GPIO_Port, &GPIO_InitStruct);

  /*Configure GPIO pins : RST_Pin GP0_Pin */
  GPIO_InitStruct.Pin = RST_Pin|GP0_Pin;
  GPIO_InitStruct.Mode = GPIO_MODE_OUTPUT_PP;
  GPIO_InitStruct.Pull = GPIO_PULLUP;
  GPIO_InitStruct.Speed = GPIO_SPEED_FREQ_LOW;
  HAL_GPIO_Init(GPIOH, &GPIO_InitStruct);

  /*Configure GPIO pin : MCU_ACTIVE_Pin */
  GPIO_InitStruct.Pin = MCU_ACTIVE_Pin;
  GPIO_InitStruct.Mode = GPIO_MODE_OUTPUT_PP;
  GPIO_InitStruct.Pull = GPIO_NOPULL;
  GPIO_InitStruct.Speed = GPIO_SPEED_FREQ_VERY_HIGH;
  HAL_GPIO_Init(MCU_ACTIVE_GPIO_Port, &GPIO_InitStruct);

  /*Configure GPIO pins : GP2_Pin CHE_Pin */
  GPIO_InitStruct.Pin = GP2_Pin|CHE_Pin;
  GPIO_InitStruct.Mode = GPIO_MODE_OUTPUT_PP;
  GPIO_InitStruct.Pull = GPIO_PULLUP;
  GPIO_InitStruct.Speed = GPIO_SPEED_FREQ_LOW;
  HAL_GPIO_Init(GPIOA, &GPIO_InitStruct);

}

/* USER CODE BEGIN 4 */

void my_snprintf(float temp, float humid, char id, char* result) {

    // Check for negative values
    bool tempSign = (temp < 0) ? true : false;
    bool humidSign = (humid < 0) ? true : false;

    temp = (temp < 0) ? (-temp) : temp;
    humid = (humid < 0) ? (-humid) : humid;

    // Round temperature and humidity to two decimal places
    uint16_t temperature = (int)(roundf(temp * 100));
    uint16_t humidityValue = (int)(roundf(humid * 100));

    // Extract the integer and decimal parts for temperature
    uint8_t temperatureInteger = temperature / 100;
    uint8_t temperatureDecimal = temperature % 100;

    // Extract the integer and decimal parts for humidity
    uint8_t humidityInteger = humidityValue / 100;
    uint8_t humidityDecimal = humidityValue % 100;
    uint8_t i = -1;
    // Format the string manually
    result[++i] = id;
    result[++i] = ' ';
    if(tempSign)
        result[++i] = '-';
    result[++i] = (temperatureInteger / 10) + '0';
    result[++i] = (temperatureInteger % 10) + '0';
    result[++i] = '.';
    result[++i] = (temperatureDecimal / 10) + '0';
    result[++i] = (temperatureDecimal % 10) + '0';
    result[++i] = ' ';
    if(humidSign)
        result[++i] = '-';
    if(humid == 100){
        result[++i] = '1';
        result[++i] = '0';
        result[++i] = '0';
    }
    else{
    result[++i] = (humidityInteger / 10) + '0';
    result[++i] = (humidityInteger % 10) + '0';
    }
    result[++i] = '.';
    result[++i] = (humidityDecimal / 10) + '0';
    result[++i] = (humidityDecimal % 10) + '0';
    result[++i] = 'q';
    result[++i] = '\0';

}
void HAL_UART_RxCpltCallback(UART_HandleTypeDef *huart){
	// Store new data in received_message buffer
	if(rx_buffer == '\0')
		rx_buffer = '0';
	osMessageQueuePut(queueRxDataCharHandle, &rx_buffer, 0, 0);
	// Re-enable IRQ
	HAL_UART_Receive_IT(&huart2, &rx_buffer,  1);
}

bool send_and_receive(char* send, char* receive, bool useSemaphore){

    // Set expected response
    osSemaphoreAcquire(semaphoreHaltUntilStringHandle, osWaitForever);
    strcpy((char*) expectedESPResponse, receive);
    osSemaphoreRelease(semaphoreHaltUntilStringHandle);

    if(useSemaphore)
    	osSemaphoreAcquire(semaphoreUARTHandle, osWaitForever);
    HAL_UART_Transmit(&huart2, (uint8_t*) send, strlen(send), HAL_MAX_DELAY);

    // wait for 5000ms to get response
    uint32_t flags = osEventFlagsWait(eventESPResponseValidHandle, EVENT_FLAG_ESP_RESPONSE_VALID,  osFlagsWaitAny, EVENT_FLAG_WAIT);

    if (flags & EVENT_FLAG_ESP_RESPONSE_VALID) {
        // Valid response received
    	if(useSemaphore)
    		osSemaphoreRelease(semaphoreUARTHandle);
    	return true;
    } else {
        // Timeout occurred
    	// Retry once
    	if(!(osEventFlagsGet(eventESPResponseHandle) & EVENT_FLAG_ESP_RESPONSE_TIMEOUT)){
        	osEventFlagsSet(eventESPResponseHandle, EVENT_FLAG_ESP_RESPONSE_TIMEOUT);
        	bool ret = send_and_receive(send, receive, false);
        	if(useSemaphore)
        		osSemaphoreRelease(semaphoreUARTHandle);
        	return ret;
    	}
    	if(useSemaphore)
    		osSemaphoreRelease(semaphoreUARTHandle);
    osEventFlagsSet(eventESPResponseHandle, EVENT_FLAG_ESP_ERROR);
    	return false;
    }
}
/* USER CODE END 4 */

void StartDefaultTask(void *argument)
{
  /* USER CODE BEGIN 5 */
  /* Infinite loop */
  for(;;)
  {
	  // Restart MCU if error occurs
	  osEventFlagsWait(eventESPResponseHandle, EVENT_FLAG_ESP_ERROR, 0, osWaitForever);
	  NVIC_SystemReset();
  }
  /* USER CODE END 5 */
}

void prvTaskSendDataWithESP(void *argument)
{
  /* USER CODE BEGIN prvTaskSendDataWithESP */
  /* Infinite loop */
	// Wait for ESP setup to finish
	osEventFlagsWait(eventESPServerConnectedHandle, EVENT_FLAG_ESP_SERVER_CONNECTED,  osFlagsWaitAny, osWaitForever);

	float temperature, humidity;

    static uint8_t dataString[16] = {'\0'} ;  // id, space, -40<temp<125, space, 00<humid<100 => max 14 char + q + '\0'
    static uint8_t cipsendString[16] = {'\0'};	// 2 digit length cipsend
  for(;;)
  {
		// Get data
	    osMessageQueueGet(queueTempAndHumidHandle, &temperature, 0, osWaitForever);
	    osMessageQueueGet(queueTempAndHumidHandle, &humidity, 0, osWaitForever);

	    // Format data into string
	    my_snprintf(temperature, humidity, BOARD_UNIQUE_ID,(char*)dataString);

	    // Format CIPSEND
	    snprintf((char*)cipsendString, 16, "AT+CIPSEND=%d\r\n", (int)strlen((char*)dataString));

	    // Send CMD to send data
	    osSemaphoreAcquire(semaphoreUARTHandle, osWaitForever);
	    send_and_receive((char*) cipsendString, ">", false);

	    // Send data
	    send_and_receive((char*) dataString, "OK\r\n", false);
	    osSemaphoreRelease(semaphoreUARTHandle);

  }
  /* USER CODE END prvTaskSendDataWithESP */
}

void prvTaskSetUpESP(void *argument)
{
  /* USER CODE BEGIN prvTaskSetUpESP */
  /* Infinite loop */
  for(;;)
  {
	  // Halts threads until setup complete
	  	// Make configurations so user doesnt have to wait so long
	  	  // Restart ESP
	  	    send_and_receive("AT+RST\r\n", "ready\r\n", true);

	  	  // Disable echo mode on ESP
	  	    send_and_receive("ATE0\r\n", "OK\r\n", true);

	  	  // Configure ESP so it is able to connect to wifi and server
	  	    send_and_receive("AT+CIPMODE=0\r\n", "OK\r\n", true);

	  	    send_and_receive("AT+CWMODE=1\r\n", "OK\r\n", true);

	  	  // Signal setup finish
	  		osEventFlagsSet(eventESPBasicSetUpFinishedHandle, EVENT_FLAG_ESP_BASIC_SETUP_FINISHED);
	  	  // Task has to run only once
	  		osThreadSuspend(SetUpESPHandle);
  }
  /* USER CODE END prvTaskSetUpESP */
}

void prvTaskReadTempAndHumidity(void *argument)
{
  /* USER CODE BEGIN prvTaskReadTempAndHumidity */
  /* Infinite loop */
	// Wait for ESP setup to finish
	osEventFlagsWait(eventESPServerConnectedHandle, EVENT_FLAG_ESP_SERVER_CONNECTED,  osFlagsWaitAny, osWaitForever);

	float temperature;
	float humidity;
  for(;;)
  {	// Read sensor data every 1 second

	 if(sht3x_read_temperature_and_humidity(&sht31, &temperature, &humidity))	{
		 osMessageQueuePut(queueTempAndHumidHandle, &temperature, 0, osWaitForever);
		 osMessageQueuePut(queueTempAndHumidHandle, &humidity, 0, osWaitForever);
		 osMessageQueuePut(queueTouchgfxTempAndHumidHandle, &temperature, 0, osWaitForever);
		 osMessageQueuePut(queueTouchgfxTempAndHumidHandle, &humidity, 0, osWaitForever);
	 }

	 // Delay for data_frequency milliseconds set by user
	 osDelay(data_frequency);
  }
  /* USER CODE END prvTaskReadTempAndHumidity */
}

void prvTaskReadESP(void *argument)
{
  /* USER CODE BEGIN prvTaskReadESP */
  /* Infinite loop */
	uint8_t rxChar = '\0';
	uint16_t received_message_index = 0;
  for(;;)
  {

	  // Add char to message
	  osMessageQueueGet(queueRxDataCharHandle, &rxChar, 0, osWaitForever);
	  // Add data to string, string is "\0" all the way
	  received_message[received_message_index++] = rxChar; // Append the character

	  // Check if got expected response
	  osSemaphoreAcquire(semaphoreHaltUntilStringHandle, osWaitForever);
	  // If message is valid, signal and clear message
	  if(strstr((char*)received_message, (char*)expectedESPResponse) != NULL){
		  osEventFlagsSet(eventESPResponseValidHandle, EVENT_FLAG_ESP_RESPONSE_VALID);
		  memset(received_message, '\0', strlen((char*)received_message));
		  received_message_index = 0;

	  }
	  else{
		  // Signal if "ERROR" is recieved
		  if(strstr((char*)received_message, "ERROR\r\n") != NULL){
		  		  osEventFlagsSet(eventESPResponseHandle, EVENT_FLAG_ESP_ERROR);
		  	  }
	  }
	  osSemaphoreRelease(semaphoreHaltUntilStringHandle);

  }
  /* USER CODE END prvTaskReadESP */
}

void prvTaskConnectToWifi(void *argument)
{
  /* USER CODE BEGIN prvTaskConnectToWifi */
  /* Infinite loop */
	char command[120];
	// Must not try before setup complete
	osEventFlagsWait(eventESPBasicSetUpFinishedHandle, EVENT_FLAG_ESP_BASIC_SETUP_FINISHED,  osFlagsWaitAny, osWaitForever);
  for(;;)
  {
  	  // Wait for user to connect
  	  	osEventFlagsWait(eventConfigurationsLoadedHandle, EVENT_FLAG_ESP_WIFI_CONNECT,  osFlagsWaitAny, osWaitForever);

  	  // Connect to WIFI
  	    snprintf(command, sizeof(command), "AT+CWJAP=\"%s\",\"%s\"\r\n", wifi_ssid, wifi_pass);
  	    send_and_receive(command, "OK", true);

  	    osEventFlagsSet(eventESPWifiConnectedHandle, EVENT_FLAG_ESP_WIFI_CONNECTED);
  }
  /* USER CODE END prvTaskConnectToWifi */
}

void prvTaskConnectToServer(void *argument)
{
  /* USER CODE BEGIN prvTaskConnectToServer */
  /* Infinite loop */
	char command[120];
	// Must not try before setup complete
	osEventFlagsWait(eventESPBasicSetUpFinishedHandle, EVENT_FLAG_ESP_BASIC_SETUP_FINISHED,  osFlagsWaitAny, osWaitForever);

  for(;;)
  {
  	  // Wait for user to connect
	  	osEventFlagsWait(eventConfigurationsLoadedHandle, EVENT_FLAG_ESP_SERVER_CONNECT,  osFlagsWaitAny, osWaitForever);
	  // must wait to be connected to wifi
		osEventFlagsWait(eventESPWifiConnectedHandle, EVENT_FLAG_ESP_WIFI_CONNECTED,  osFlagsWaitAny, osWaitForever);
  	  //Connect to server
  	    snprintf(command, sizeof(command), "AT+CIPSTART=\"TCP\",\"%s\",%s\r\n", server_ip, server_port);
  	    send_and_receive(command, "OK\r\n", true);

  	  osEventFlagsSet(eventESPServerConnectedHandle, EVENT_FLAG_ESP_SERVER_CONNECTED);
  }
  /* USER CODE END prvTaskConnectToServer */
}

void prvTaskDisconnect(void *argument)
{
  /* USER CODE BEGIN prvTaskDisconnect */
  /* Infinite loop */
  for(;;)
  {
    osEventFlagsWait(eventDisconnectHandle, EVENT_FLAG_DISCONNECT_REQUEST, osFlagsWaitAny, osWaitForever);

    // Disconnect from server
    send_and_receive("AT+CIPCLOSE\r\n", "OK\r\n", false);

    // Disconnect from wifi
	send_and_receive("AT+CWQAP\r\n", "OK", true);
    // Signal successful disconnection
    osEventFlagsSet(eventDisconnectHandle, EVENT_FLAG_DISCONNECT_SUCCESSFUL);
    osThreadSuspend(SendDataWithESPHandle);
    osThreadSuspend(ReadSensorDataHandle);
  }
  /* USER CODE END prvTaskDisconnect */
}

/* MPU Configuration */

void MPU_Config(void)
{
  MPU_Region_InitTypeDef MPU_InitStruct = {0};

  /* Disables the MPU */
  HAL_MPU_Disable();

  /** Initializes and configures the Region and the memory to be protected
  */
  MPU_InitStruct.Enable = MPU_REGION_ENABLE;
  MPU_InitStruct.Number = MPU_REGION_NUMBER0;
  MPU_InitStruct.BaseAddress = 0x24000000;
  MPU_InitStruct.Size = MPU_REGION_SIZE_512KB;
  MPU_InitStruct.SubRegionDisable = 0x0;
  MPU_InitStruct.TypeExtField = MPU_TEX_LEVEL0;
  MPU_InitStruct.AccessPermission = MPU_REGION_FULL_ACCESS;
  MPU_InitStruct.DisableExec = MPU_INSTRUCTION_ACCESS_DISABLE;
  MPU_InitStruct.IsShareable = MPU_ACCESS_NOT_SHAREABLE;
  MPU_InitStruct.IsCacheable = MPU_ACCESS_CACHEABLE;
  MPU_InitStruct.IsBufferable = MPU_ACCESS_BUFFERABLE;

  HAL_MPU_ConfigRegion(&MPU_InitStruct);

  /** Initializes and configures the Region and the memory to be protected
  */
  MPU_InitStruct.Number = MPU_REGION_NUMBER1;
  MPU_InitStruct.BaseAddress = 0x90000000;
  MPU_InitStruct.Size = MPU_REGION_SIZE_256MB;
  MPU_InitStruct.AccessPermission = MPU_REGION_NO_ACCESS;
  MPU_InitStruct.IsCacheable = MPU_ACCESS_NOT_CACHEABLE;
  MPU_InitStruct.IsBufferable = MPU_ACCESS_NOT_BUFFERABLE;

  HAL_MPU_ConfigRegion(&MPU_InitStruct);

  /** Initializes and configures the Region and the memory to be protected
  */
  MPU_InitStruct.Number = MPU_REGION_NUMBER2;
  MPU_InitStruct.Size = MPU_REGION_SIZE_128MB;
  MPU_InitStruct.AccessPermission = MPU_REGION_FULL_ACCESS;
  MPU_InitStruct.DisableExec = MPU_INSTRUCTION_ACCESS_ENABLE;
  MPU_InitStruct.IsCacheable = MPU_ACCESS_CACHEABLE;
  MPU_InitStruct.IsBufferable = MPU_ACCESS_BUFFERABLE;

  HAL_MPU_ConfigRegion(&MPU_InitStruct);

  /** Initializes and configures the Region and the memory to be protected
  */
  MPU_InitStruct.Number = MPU_REGION_NUMBER3;
  MPU_InitStruct.BaseAddress = 0xD0000000;
  MPU_InitStruct.Size = MPU_REGION_SIZE_256MB;
  MPU_InitStruct.AccessPermission = MPU_REGION_NO_ACCESS;
  MPU_InitStruct.DisableExec = MPU_INSTRUCTION_ACCESS_DISABLE;
  MPU_InitStruct.IsCacheable = MPU_ACCESS_NOT_CACHEABLE;
  MPU_InitStruct.IsBufferable = MPU_ACCESS_NOT_BUFFERABLE;

  HAL_MPU_ConfigRegion(&MPU_InitStruct);

  /** Initializes and configures the Region and the memory to be protected
  */
  MPU_InitStruct.Number = MPU_REGION_NUMBER4;
  MPU_InitStruct.Size = MPU_REGION_SIZE_32MB;
  MPU_InitStruct.AccessPermission = MPU_REGION_FULL_ACCESS;
  MPU_InitStruct.IsCacheable = MPU_ACCESS_CACHEABLE;

  HAL_MPU_ConfigRegion(&MPU_InitStruct);
  /* Enables the MPU */
  HAL_MPU_Enable(MPU_PRIVILEGED_DEFAULT);

}

void HAL_TIM_PeriodElapsedCallback(TIM_HandleTypeDef *htim)
{
  if (htim->Instance == TIM6) {
    HAL_IncTick();
  }
}

void Error_Handler(void)
{
}
